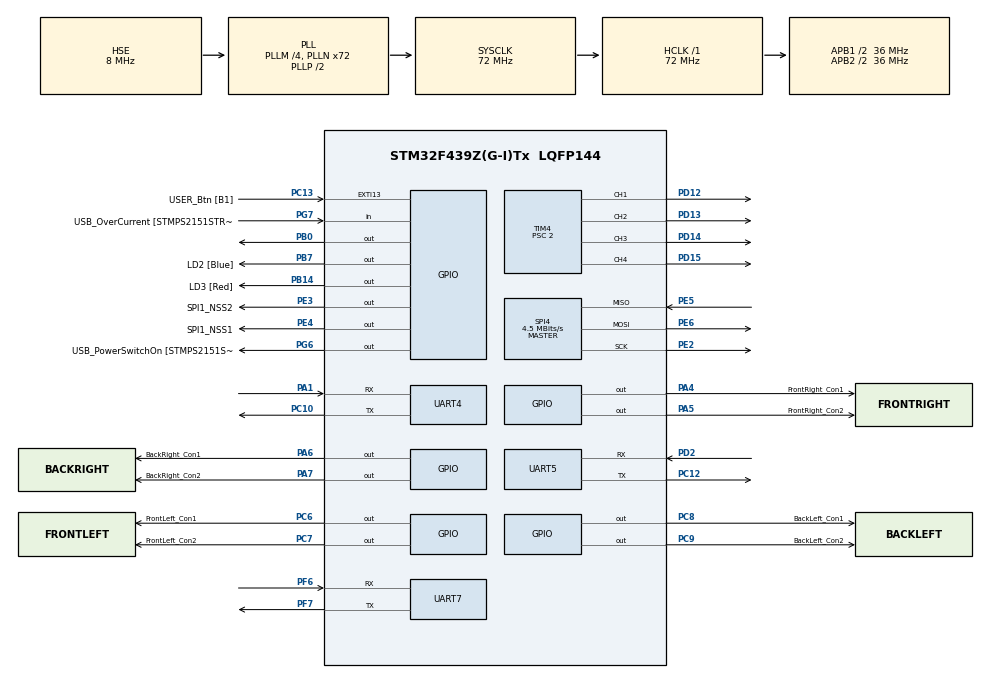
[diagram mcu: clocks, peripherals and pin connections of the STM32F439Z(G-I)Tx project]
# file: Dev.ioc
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Dma.Request0=UART5_RX
Dma.Request1=UART4_RX
Dma.Request2=UART7_TX
Dma.Request3=SPI4_RX
Dma.Request4=SPI4_TX
Dma.SPI4_RX.3.Direction=DMA_PERIPH_TO_MEMORY
Dma.SPI4_RX.3.FIFOMode=DMA_FIFOMODE_DISABLE
Dma.SPI4_RX.3.Instance=DMA2_Stream0
Dma.SPI4_RX.3.MemDataAlignment=DMA_MDATAALIGN_BYTE
Dma.SPI4_RX.3.MemInc=DMA_MINC_ENABLE
Dma.SPI4_RX.3.Mode=DMA_NORMAL
Dma.SPI4_RX.3.PeriphDataAlignment=DMA_PDATAALIGN_BYTE
Dma.SPI4_RX.3.PeriphInc=DMA_PINC_DISABLE
Dma.SPI4_RX.3.Priority=DMA_PRIORITY_LOW
Dma.SPI4_TX.4.Direction=DMA_MEMORY_TO_PERIPH
Dma.SPI4_TX.4.FIFOMode=DMA_FIFOMODE_DISABLE
Dma.SPI4_TX.4.Instance=DMA2_Stream1
Dma.SPI4_TX.4.MemDataAlignment=DMA_MDATAALIGN_BYTE
Dma.SPI4_TX.4.MemInc=DMA_MINC_ENABLE
Dma.SPI4_TX.4.Mode=DMA_NORMAL
Dma.SPI4_TX.4.PeriphDataAlignment=DMA_PDATAALIGN_BYTE
Dma.SPI4_TX.4.PeriphInc=DMA_PINC_DISABLE
Dma.SPI4_TX.4.Priority=DMA_PRIORITY_LOW
Dma.UART4_RX.1.Direction=DMA_PERIPH_TO_MEMORY
Dma.UART4_RX.1.FIFOMode=DMA_FIFOMODE_DISABLE
Dma.UART4_RX.1.Instance=DMA1_Stream2
Dma.UART4_RX.1.MemDataAlignment=DMA_MDATAALIGN_BYTE
Dma.UART4_RX.1.MemInc=DMA_MINC_ENABLE
Dma.UART4_RX.1.Mode=DMA_NORMAL
Dma.UART4_RX.1.PeriphDataAlignment=DMA_PDATAALIGN_BYTE
Dma.UART4_RX.1.PeriphInc=DMA_PINC_DISABLE
Dma.UART4_RX.1.Priority=DMA_PRIORITY_LOW
Dma.UART5_RX.0.Direction=DMA_PERIPH_TO_MEMORY
Dma.UART5_RX.0.FIFOMode=DMA_FIFOMODE_DISABLE
Dma.UART5_RX.0.Instance=DMA1_Stream0
Dma.UART5_RX.0.MemDataAlignment=DMA_MDATAALIGN_BYTE
Dma.UART5_RX.0.MemInc=DMA_MINC_ENABLE
Dma.UART5_RX.0.Mode=DMA_NORMAL
Dma.UART5_RX.0.PeriphDataAlignment=DMA_PDATAALIGN_BYTE
Dma.UART5_RX.0.PeriphInc=DMA_PINC_DISABLE
Dma.UART5_RX.0.Priority=DMA_PRIORITY_LOW
Dma.UART7_TX.2.Direction=DMA_MEMORY_TO_PERIPH
Dma.UART7_TX.2.FIFOMode=DMA_FIFOMODE_DISABLE
Dma.UART7_TX.2.Instance=DMA1_Stream1
Dma.UART7_TX.2.MemDataAlignment=DMA_MDATAALIGN_BYTE
Dma.UART7_TX.2.MemInc=DMA_MINC_ENABLE
Dma.UART7_TX.2.Mode=DMA_NORMAL
Dma.UART7_TX.2.PeriphDataAlignment=DMA_PDATAALIGN_BYTE
Dma.UART7_TX.2.PeriphInc=DMA_PINC_DISABLE
Dma.UART7_TX.2.Priority=DMA_PRIORITY_LOW
Mcu.Family=STM32F4
Mcu.Name=STM32F439Z(G-I)Tx
Mcu.Package=LQFP144
NVIC.DMA1_Stream0_IRQn=true\:0\:0\:false\:false\:true\:false\:true\:true
NVIC.DMA1_Stream1_IRQn=true\:0\:0\:false\:false\:true\:false\:true\:true
NVIC.DMA1_Stream2_IRQn=true\:0\:0\:false\:false\:true\:false\:true\:true
NVIC.DMA2_Stream0_IRQn=true\:0\:0\:false\:false\:true\:false\:true\:true
NVIC.DMA2_Stream1_IRQn=true\:0\:0\:false\:false\:true\:false\:true\:true
NVIC.PriorityGroup=NVIC_PRIORITYGROUP_4
PA1.Mode=Asynchronous
PA1.Signal=UART4_RX
PA13.GPIO_Label=TMS
PA13.Mode=Serial_Wire
PA13.Signal=SYS_JTMS-SWDIO
PA14.GPIO_Label=TCK
PA14.Mode=Serial_Wire
PA14.Signal=SYS_JTCK-SWCLK
PA4.GPIO_Label=FrontRight_Con1
PA4.PinState=GPIO_PIN_RESET
PA4.Signal=GPIO_Output
PA5.GPIO_Label=FrontRight_Con2
PA5.Signal=GPIO_Output
PA6.GPIO_Label=BackRight_Con1
PA6.Signal=GPIO_Output
PA7.GPIO_Label=BackRight_Con2
PA7.Signal=GPIO_Output
PB0.Signal=GPIO_Output
PB14.GPIO_Label=LD3 [Red]
PB14.Signal=GPIO_Output
PB7.GPIO_Label=LD2 [Blue]
PB7.Signal=GPIO_Output
PC10.Mode=Asynchronous
PC10.Signal=UART4_TX
PC12.Mode=Asynchronous
PC12.Signal=UART5_TX
PC13.GPIO_Label=USER_Btn [B1]
PC13.Signal=GPXTI13
PC6.GPIO_Label=FrontLeft_Con1
PC6.Signal=GPIO_Output
PC7.GPIO_Label=FrontLeft_Con2
PC7.Signal=GPIO_Output
PC8.GPIO_Label=BackLeft_Con1
PC8.Signal=GPIO_Output
PC9.GPIO_Label=BackLeft_Con2
PC9.Signal=GPIO_Output
PD12.Signal=S_TIM4_CH1
PD13.Signal=S_TIM4_CH2
PD14.Signal=S_TIM4_CH3
PD15.Signal=S_TIM4_CH4
PD2.Mode=Asynchronous
PD2.Signal=UART5_RX
PE2.Mode=Full_Duplex_Master
PE2.Signal=SPI4_SCK
PE3.GPIO_Label=SPI1_NSS2
PE3.PinState=GPIO_PIN_SET
PE3.Signal=GPIO_Output
PE4.GPIO_Label=SPI1_NSS1
PE4.PinState=GPIO_PIN_SET
PE4.Signal=GPIO_Output
PE5.Mode=Full_Duplex_Master
PE5.Signal=SPI4_MISO
PE6.Mode=Full_Duplex_Master
PE6.Signal=SPI4_MOSI
PF6.Mode=Asynchronous
PF6.Signal=UART7_RX
PF7.Mode=Asynchronous
PF7.Signal=UART7_TX
PG6.GPIO_Label=USB_PowerSwitchOn [STMPS2151STR_EN]
PG6.Signal=GPIO_Output
PG7.GPIO_Label=USB_OverCurrent [STMPS2151STR_FAULT]
PG7.Signal=GPIO_Input
PH0/OSC_IN.Mode=HSE-External-Oscillator
PH0/OSC_IN.Signal=RCC_OSC_IN
PH1/OSC_OUT.Mode=HSE-External-Oscillator
PH1/OSC_OUT.Signal=RCC_OSC_OUT
ProjectManager.HeapSize=0x200
ProjectManager.StackSize=0x400
ProjectManager.TargetToolchain=STM32CubeIDE
RCC.48MHZClocksFreq_Value=36000000
RCC.AHBFreq_Value=72000000
RCC.APB1CLKDivider=RCC_HCLK_DIV2
RCC.APB1Freq_Value=36000000
RCC.APB1TimFreq_Value=72000000
RCC.APB2CLKDivider=RCC_HCLK_DIV2
RCC.APB2Freq_Value=36000000
RCC.APB2TimFreq_Value=72000000
RCC.CortexFreq_Value=72000000
RCC.HCLKFreq_Value=72000000
RCC.HSE_VALUE=8000000
RCC.HSI_VALUE=16000000
RCC.LSE_VALUE=32768
RCC.PLLM=4
RCC.PLLN=72
RCC.PLLSourceVirtual=RCC_PLLSOURCE_HSE
RCC.SYSCLKFreq_VALUE=72000000
RCC.SYSCLKSource=RCC_SYSCLKSOURCE_PLLCLK
RCC.VCOOutputFreq_Value=144000000
SH.S_TIM4_CH1.0=TIM4_CH1,PWM Generation1 CH1
SH.S_TIM4_CH2.0=TIM4_CH2,PWM Generation2 CH2
SH.S_TIM4_CH3.0=TIM4_CH3,PWM Generation3 CH3
SH.S_TIM4_CH4.0=TIM4_CH4,PWM Generation4 CH4
SPI4.BaudRatePrescaler=SPI_BAUDRATEPRESCALER_8
SPI4.CLKPolarity=SPI_POLARITY_HIGH
SPI4.CalculateBaudRate=4.5 MBits/s
SPI4.DataSize=SPI_DATASIZE_8BIT
SPI4.Direction=SPI_DIRECTION_2LINES
SPI4.Mode=SPI_MODE_MASTER
SPI4.VirtualType=VM_MASTER
TIM4.Channel-PWM\ Generation1\ CH1=TIM_CHANNEL_1
TIM4.Channel-PWM\ Generation2\ CH2=TIM_CHANNEL_2
TIM4.Channel-PWM\ Generation3\ CH3=TIM_CHANNEL_3
TIM4.Channel-PWM\ Generation4\ CH4=TIM_CHANNEL_4
TIM4.Prescaler=2
UART4.VirtualMode=Asynchronous
UART5.VirtualMode=Asynchronous
UART7.VirtualMode=Asynchronous
VP_TIM4_VS_ClockSourceINT.Mode=Internal
board=NUCLEO-F439ZI

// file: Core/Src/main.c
/* USER CODE BEGIN Header */
/**
  ******************************************************************************
  * @file           : main.c
  * @brief          : Main program body
  ******************************************************************************
  * @attention
  *
  * Copyright (c) 2025 STMicroelectronics.
  * All rights reserved.
  *
  * This software is licensed under terms that can be found in the LICENSE file
  * in the root directory of this software component.
  * If no LICENSE file comes with this software, it is provided AS-IS.
  *
  ******************************************************************************
  */
/* USER CODE END Header */
#include "main.h"

SPI_HandleTypeDef hspi4;
DMA_HandleTypeDef hdma_spi4_rx;
DMA_HandleTypeDef hdma_spi4_tx;

TIM_HandleTypeDef htim4;

UART_HandleTypeDef huart4;
UART_HandleTypeDef huart5;
UART_HandleTypeDef huart7;
DMA_HandleTypeDef hdma_uart4_rx;
DMA_HandleTypeDef hdma_uart5_rx;
DMA_HandleTypeDef hdma_uart7_tx;

void SystemClock_Config(void);
static void MX_GPIO_Init(void);
static void MX_DMA_Init(void);
static void MX_UART4_Init(void);
static void MX_UART5_Init(void);
static void MX_UART7_Init(void);
static void MX_TIM4_Init(void);
static void MX_SPI4_Init(void);

int main(void)
{

  /* USER CODE BEGIN 1 */
	//HAL_StatusTypeDef retVal = HAL_OK;
  /* USER CODE END 1 */

  /* MCU Configuration--------------------------------------------------------*/

  /* Reset of all peripherals, Initializes the Flash interface and the Systick. */
  HAL_Init();

  /* Configure the system clock */
  SystemClock_Config();

  /* Initialize all configured peripherals */
  MX_GPIO_Init();
  MX_DMA_Init();
  MX_UART4_Init();
  MX_UART5_Init();
  MX_UART7_Init();
  MX_TIM4_Init();
  MX_SPI4_Init();
  /* USER CODE BEGIN 2 */
  OpenMV_Init();

  /* USER CODE END 2 */

  /* Infinite loop */
  while (1)
  {

    /* USER CODE BEGIN 3 */
	  HAL_GPIO_TogglePin(GPIOB, LD3_Pin);
	  OpenMV_SPI_MainFunction(&hspi4);
	  MotDrv_TakeDecision(cameraData1, cameraData2);
  }
  /* USER CODE END 3 */
}

void SystemClock_Config(void)
{
  RCC_OscInitTypeDef RCC_OscInitStruct = {0};
  RCC_ClkInitTypeDef RCC_ClkInitStruct = {0};

  /** Configure the main internal regulator output voltage
  */
  __HAL_RCC_PWR_CLK_ENABLE();
  __HAL_PWR_VOLTAGESCALING_CONFIG(PWR_REGULATOR_VOLTAGE_SCALE3);

  /** Initializes the RCC Oscillators according to the specified parameters
  * in the RCC_OscInitTypeDef structure.
  */
  RCC_OscInitStruct.OscillatorType = RCC_OSCILLATORTYPE_HSE;
  RCC_OscInitStruct.HSEState = RCC_HSE_ON;
  RCC_OscInitStruct.PLL.PLLState = RCC_PLL_ON;
  RCC_OscInitStruct.PLL.PLLSource = RCC_PLLSOURCE_HSE;
  RCC_OscInitStruct.PLL.PLLM = 4;
  RCC_OscInitStruct.PLL.PLLN = 72;
  RCC_OscInitStruct.PLL.PLLP = RCC_PLLP_DIV2;
  RCC_OscInitStruct.PLL.PLLQ = 4;
  if (HAL_RCC_OscConfig(&RCC_OscInitStruct) != HAL_OK)
  {
    Error_Handler();
  }

  /** Initializes the CPU, AHB and APB buses clocks
  */
  RCC_ClkInitStruct.ClockType = RCC_CLOCKTYPE_HCLK|RCC_CLOCKTYPE_SYSCLK
                              |RCC_CLOCKTYPE_PCLK1|RCC_CLOCKTYPE_PCLK2;
  RCC_ClkInitStruct.SYSCLKSource = RCC_SYSCLKSOURCE_PLLCLK;
  RCC_ClkInitStruct.AHBCLKDivider = RCC_SYSCLK_DIV1;
  RCC_ClkInitStruct.APB1CLKDivider = RCC_HCLK_DIV2;
  RCC_ClkInitStruct.APB2CLKDivider = RCC_HCLK_DIV2;

  if (HAL_RCC_ClockConfig(&RCC_ClkInitStruct, FLASH_LATENCY_2) != HAL_OK)
  {
    Error_Handler();
  }
}

static void MX_SPI4_Init(void)
{

  /* SPI4 parameter configuration*/
  hspi4.Instance = SPI4;
  hspi4.Init.Mode = SPI_MODE_MASTER;
  hspi4.Init.Direction = SPI_DIRECTION_2LINES;
  hspi4.Init.DataSize = SPI_DATASIZE_8BIT;
  hspi4.Init.CLKPolarity = SPI_POLARITY_HIGH;
  hspi4.Init.CLKPhase = SPI_PHASE_1EDGE;
  hspi4.Init.NSS = SPI_NSS_SOFT;
  hspi4.Init.BaudRatePrescaler = SPI_BAUDRATEPRESCALER_8;
  hspi4.Init.FirstBit = SPI_FIRSTBIT_MSB;
  hspi4.Init.TIMode = SPI_TIMODE_DISABLE;
  hspi4.Init.CRCCalculation = SPI_CRCCALCULATION_DISABLE;
  hspi4.Init.CRCPolynomial = 10;
  if (HAL_SPI_Init(&hspi4) != HAL_OK)
  {
    Error_Handler();
  }

}

static void MX_TIM4_Init(void)
{

  TIM_ClockConfigTypeDef sClockSourceConfig = {0};
  TIM_MasterConfigTypeDef sMasterConfig = {0};
  TIM_OC_InitTypeDef sConfigOC = {0};

  htim4.Instance = TIM4;
  htim4.Init.Prescaler = 2;
  htim4.Init.CounterMode = TIM_COUNTERMODE_UP;
  htim4.Init.Period = 65535;
  htim4.Init.ClockDivision = TIM_CLOCKDIVISION_DIV1;
  htim4.Init.AutoReloadPreload = TIM_AUTORELOAD_PRELOAD_DISABLE;
  if (HAL_TIM_Base_Init(&htim4) != HAL_OK)
  {
    Error_Handler();
  }
  sClockSourceConfig.ClockSource = TIM_CLOCKSOURCE_INTERNAL;
  if (HAL_TIM_ConfigClockSource(&htim4, &sClockSourceConfig) != HAL_OK)
  {
    Error_Handler();
  }
  if (HAL_TIM_PWM_Init(&htim4) != HAL_OK)
  {
    Error_Handler();
  }
  sMasterConfig.MasterOutputTrigger = TIM_TRGO_RESET;
  sMasterConfig.MasterSlaveMode = TIM_MASTERSLAVEMODE_DISABLE;
  if (HAL_TIMEx_MasterConfigSynchronization(&htim4, &sMasterConfig) != HAL_OK)
  {
    Error_Handler();
  }
  sConfigOC.OCMode = TIM_OCMODE_PWM1;
  sConfigOC.Pulse = 0;
  sConfigOC.OCPolarity = TIM_OCPOLARITY_HIGH;
  sConfigOC.OCFastMode = TIM_OCFAST_DISABLE;
  if (HAL_TIM_PWM_ConfigChannel(&htim4, &sConfigOC, TIM_CHANNEL_1) != HAL_OK)
  {
    Error_Handler();
  }
  if (HAL_TIM_PWM_ConfigChannel(&htim4, &sConfigOC, TIM_CHANNEL_2) != HAL_OK)
  {
    Error_Handler();
  }
  if (HAL_TIM_PWM_ConfigChannel(&htim4, &sConfigOC, TIM_CHANNEL_3) != HAL_OK)
  {
    Error_Handler();
  }
  if (HAL_TIM_PWM_ConfigChannel(&htim4, &sConfigOC, TIM_CHANNEL_4) != HAL_OK)
  {
    Error_Handler();
  }
  HAL_TIM_MspPostInit(&htim4);

}

static void MX_UART4_Init(void)
{

  huart4.Instance = UART4;
  huart4.Init.BaudRate = 115200;
  huart4.Init.WordLength = UART_WORDLENGTH_8B;
  huart4.Init.StopBits = UART_STOPBITS_1;
  huart4.Init.Parity = UART_PARITY_NONE;
  huart4.Init.Mode = UART_MODE_TX_RX;
  huart4.Init.HwFlowCtl = UART_HWCONTROL_NONE;
  huart4.Init.OverSampling = UART_OVERSAMPLING_16;
  if (HAL_UART_Init(&huart4) != HAL_OK)
  {
    Error_Handler();
  }

}

static void MX_UART5_Init(void)
{

  huart5.Instance = UART5;
  huart5.Init.BaudRate = 115200;
  huart5.Init.WordLength = UART_WORDLENGTH_8B;
  huart5.Init.StopBits = UART_STOPBITS_1;
  huart5.Init.Parity = UART_PARITY_NONE;
  huart5.Init.Mode = UART_MODE_TX_RX;
  huart5.Init.HwFlowCtl = UART_HWCONTROL_NONE;
  huart5.Init.OverSampling = UART_OVERSAMPLING_16;
  if (HAL_UART_Init(&huart5) != HAL_OK)
  {
    Error_Handler();
  }

}

static void MX_UART7_Init(void)
{

  huart7.Instance = UART7;
  huart7.Init.BaudRate = 115200;
  huart7.Init.WordLength = UART_WORDLENGTH_8B;
  huart7.Init.StopBits = UART_STOPBITS_1;
  huart7.Init.Parity = UART_PARITY_NONE;
  huart7.Init.Mode = UART_MODE_TX_RX;
  huart7.Init.HwFlowCtl = UART_HWCONTROL_NONE;
  huart7.Init.OverSampling = UART_OVERSAMPLING_16;
  if (HAL_UART_Init(&huart7) != HAL_OK)
  {
    Error_Handler();
  }

}

static void MX_DMA_Init(void)
{

  /* DMA controller clock enable */
  __HAL_RCC_DMA1_CLK_ENABLE();
  __HAL_RCC_DMA2_CLK_ENABLE();

  /* DMA interrupt init */
  /* DMA1_Stream0_IRQn interrupt configuration */
  HAL_NVIC_SetPriority(DMA1_Stream0_IRQn, 0, 0);
  HAL_NVIC_EnableIRQ(DMA1_Stream0_IRQn);
  /* DMA1_Stream1_IRQn interrupt configuration */
  HAL_NVIC_SetPriority(DMA1_Stream1_IRQn, 0, 0);
  HAL_NVIC_EnableIRQ(DMA1_Stream1_IRQn);
  /* DMA1_Stream2_IRQn interrupt configuration */
  HAL_NVIC_SetPriority(DMA1_Stream2_IRQn, 0, 0);
  HAL_NVIC_EnableIRQ(DMA1_Stream2_IRQn);
  /* DMA2_Stream0_IRQn interrupt configuration */
  HAL_NVIC_SetPriority(DMA2_Stream0_IRQn, 0, 0);
  HAL_NVIC_EnableIRQ(DMA2_Stream0_IRQn);
  /* DMA2_Stream1_IRQn interrupt configuration */
  HAL_NVIC_SetPriority(DMA2_Stream1_IRQn, 0, 0);
  HAL_NVIC_EnableIRQ(DMA2_Stream1_IRQn);

}

static void MX_GPIO_Init(void)
{
  GPIO_InitTypeDef GPIO_InitStruct = {0};

  /* GPIO Ports Clock Enable */
  __HAL_RCC_GPIOE_CLK_ENABLE();
  __HAL_RCC_GPIOC_CLK_ENABLE();
  __HAL_RCC_GPIOF_CLK_ENABLE();
  __HAL_RCC_GPIOH_CLK_ENABLE();
  __HAL_RCC_GPIOA_CLK_ENABLE();
  __HAL_RCC_GPIOB_CLK_ENABLE();
  __HAL_RCC_GPIOD_CLK_ENABLE();
  __HAL_RCC_GPIOG_CLK_ENABLE();

  /*Configure GPIO pin Output Level */
  HAL_GPIO_WritePin(GPIOE, SPI1_NSS2_Pin|SPI1_NSS1_Pin, GPIO_PIN_SET);

  /*Configure GPIO pin Output Level */
  HAL_GPIO_WritePin(GPIOA, FrontRight_Con1_Pin|FrontRight_Con2_Pin|BackRight_Con1_Pin|BackRight_Con2_Pin, GPIO_PIN_RESET);

  /*Configure GPIO pin Output Level */
  HAL_GPIO_WritePin(GPIOB, GPIO_PIN_0|LD3_Pin|LD2_Pin, GPIO_PIN_RESET);

  /*Configure GPIO pin Output Level */
  HAL_GPIO_WritePin(USB_PowerSwitchOn_GPIO_Port, USB_PowerSwitchOn_Pin, GPIO_PIN_RESET);

  /*Configure GPIO pin Output Level */
  HAL_GPIO_WritePin(GPIOC, FrontLeft_Con1_Pin|FrontLeft_Con2_Pin|BackLeft_Con1_Pin|BackLeft_Con2_Pin, GPIO_PIN_RESET);

  /*Configure GPIO pins : SPI1_NSS2_Pin SPI1_NSS1_Pin */
  GPIO_InitStruct.Pin = SPI1_NSS2_Pin|SPI1_NSS1_Pin;
  GPIO_InitStruct.Mode = GPIO_MODE_OUTPUT_PP;
  GPIO_InitStruct.Pull = GPIO_NOPULL;
  GPIO_InitStruct.Speed = GPIO_SPEED_FREQ_LOW;
  HAL_GPIO_Init(GPIOE, &GPIO_InitStruct);

  /*Configure GPIO pin : USER_Btn_Pin */
  GPIO_InitStruct.Pin = USER_Btn_Pin;
  GPIO_InitStruct.Mode = GPIO_MODE_IT_RISING;
  GPIO_InitStruct.Pull = GPIO_NOPULL;
  HAL_GPIO_Init(USER_Btn_GPIO_Port, &GPIO_InitStruct);

  /*Configure GPIO pins : FrontRight_Con1_Pin FrontRight_Con2_Pin BackRight_Con1_Pin BackRight_Con2_Pin */
  GPIO_InitStruct.Pin = FrontRight_Con1_Pin|FrontRight_Con2_Pin|BackRight_Con1_Pin|BackRight_Con2_Pin;
  GPIO_InitStruct.Mode = GPIO_MODE_OUTPUT_PP;
  GPIO_InitStruct.Pull = GPIO_NOPULL;
  GPIO_InitStruct.Speed = GPIO_SPEED_FREQ_LOW;
  HAL_GPIO_Init(GPIOA, &GPIO_InitStruct);

  /*Configure GPIO pins : PB0 LD3_Pin LD2_Pin */
  GPIO_InitStruct.Pin = GPIO_PIN_0|LD3_Pin|LD2_Pin;
  GPIO_InitStruct.Mode = GPIO_MODE_OUTPUT_PP;
  GPIO_InitStruct.Pull = GPIO_NOPULL;
  GPIO_InitStruct.Speed = GPIO_SPEED_FREQ_LOW;
  HAL_GPIO_Init(GPIOB, &GPIO_InitStruct);

  /*Configure GPIO pin : USB_PowerSwitchOn_Pin */
  GPIO_InitStruct.Pin = USB_PowerSwitchOn_Pin;
  GPIO_InitStruct.Mode = GPIO_MODE_OUTPUT_PP;
  GPIO_InitStruct.Pull = GPIO_NOPULL;
  GPIO_InitStruct.Speed = GPIO_SPEED_FREQ_LOW;
  HAL_GPIO_Init(USB_PowerSwitchOn_GPIO_Port, &GPIO_InitStruct);

  /*Configure GPIO pin : USB_OverCurrent_Pin */
  GPIO_InitStruct.Pin = USB_OverCurrent_Pin;
  GPIO_InitStruct.Mode = GPIO_MODE_INPUT;
  GPIO_InitStruct.Pull = GPIO_NOPULL;
  HAL_GPIO_Init(USB_OverCurrent_GPIO_Port, &GPIO_InitStruct);

  /*Configure GPIO pins : FrontLeft_Con1_Pin FrontLeft_Con2_Pin BackLeft_Con1_Pin BackLeft_Con2_Pin */
  GPIO_InitStruct.Pin = FrontLeft_Con1_Pin|FrontLeft_Con2_Pin|BackLeft_Con1_Pin|BackLeft_Con2_Pin;
  GPIO_InitStruct.Mode = GPIO_MODE_OUTPUT_PP;
  GPIO_InitStruct.Pull = GPIO_NOPULL;
  GPIO_InitStruct.Speed = GPIO_SPEED_FREQ_LOW;
  HAL_GPIO_Init(GPIOC, &GPIO_InitStruct);

}

/* USER CODE BEGIN 4 */
int _write(int file, char *ptr, int len)
{
  (void)file;
  int DataIdx;

  for (DataIdx = 0; DataIdx < len; DataIdx++)
  {
    ITM_SendChar(*ptr++);
  }
  return len;
}

/* USER CODE END 4 */

void Error_Handler(void)
{
  __disable_irq();
  while (1)
  {
  }
}
